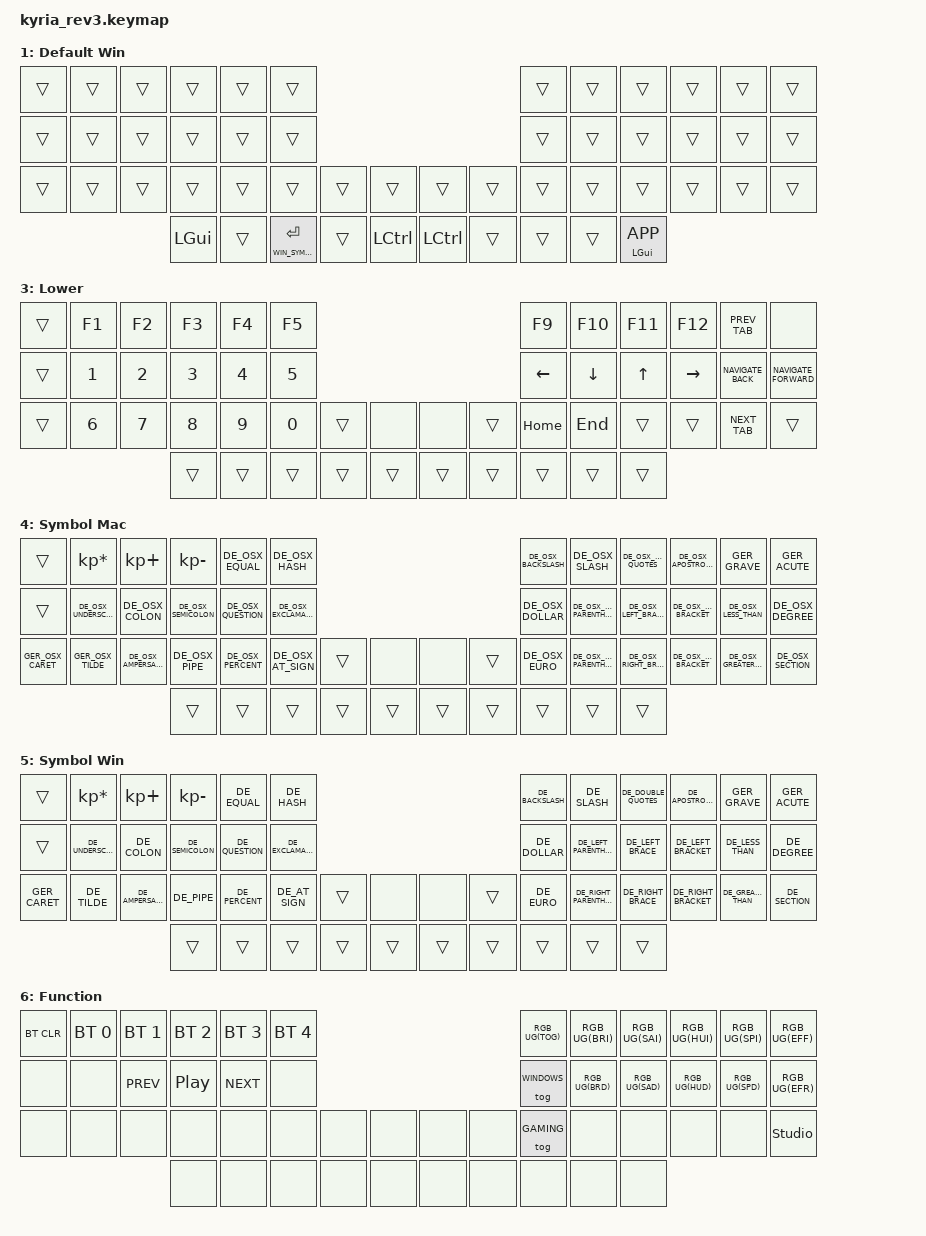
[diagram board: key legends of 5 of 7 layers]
/*
 * Copyright (c) 2023 The ZMK Contributors
 *
 * SPDX-License-Identifier: MIT
 */

#include <behaviors.dtsi>
#include <dt-bindings/zmk/bt.h>
#include <dt-bindings/zmk/keys.h>
#include <dt-bindings/zmk/rgb.h>

// https://github.com/joelspadin/zmk-locale-generator v1.4.0
#include "keys_de.h"
#include "keys_de_osx.h"

// Uncomment this block if using RGB
&led_strip {
    chain-length = <6>;
    // chain-length = <31>; // Uncomment if using both per-key and underglow LEDs
    // chain-length = <25>; // Uncomment if using only per-key LEDs.
};

&sensors {
    triggers-per-rotation = <36>;
};

// DIFFICULTY_THRESHOLD specifies your level of expertise with this keymap.
// It's meant to help newcomers gradually work their way up to mastery.
// You can disable this setting by omitting it or assigning a `0` zero.
#define DIFFICULTY_THRESHOLD 250 // 500ms: easy -> 100ms: hard

#if defined(DIFFICULTY_THRESHOLD) && DIFFICULTY_THRESHOLD > 0

    #define HOLDING_TIME DIFFICULTY_THRESHOLD

    #define PINKEY_DIFFICULTY_OFFSET (DIFFICULTY_THRESHOLD / 8)

    #define TAP_DANCE_TAPPING_TIME (DIFFICULTY_THRESHOLD - 25)

#else

    #define PINKEY_DIFFICULTY_OFFSET 0

    #define TAP_DANCE_TAPPING_TIME 200

#endif

//////////////////////////////////////////////////////////////////////////
//
// Miryoku layers and home row mods (ported from my QMK endgame)
// - https://sunaku.github.io/home-row-mods.html#porting-to-zmk
// - https://github.com/urob/zmk-config#timeless-homerow-mods
//
//////////////////////////////////////////////////////////////////////////

// HOLDING_TYPE defines the flavor of ZMK hold-tap behavior to use
// for the pinky, ring, and middle fingers (which are assigned to Super,
// Alt, and Ctrl respectively in the Miryoku system) on home row keys.
#define HOLDING_TYPE "tap-preferred"

// HOLDING_TIME defines how long you need to hold (milliseconds)
// home row mod keys in order to send their modifiers to the computer
// (i.e. "register" them) for mod-click mouse usage (e.g. Ctrl-Click).
#ifndef HOLDING_TIME
    #define HOLDING_TIME 270 // TAPPING_TERM + ALLOW_CROSSOVER_AFTER
#endif

// STREAK_DECAY defines how long you need to wait (milliseconds)
// after typing before you can use home row mods again. It prevents
// unintended activation of home row mods when you're actively typing.
#define STREAK_DECAY 250

// REPEAT_DECAY defines how much time you have left (milliseconds)
// after tapping a key to hold it again in order to make it auto-repeat.
#define REPEAT_DECAY 150 // "tap then hold" for key auto-repeat

// Home row mods
/ {
    behaviors {
        /*
           key positions index for positional hold-tap

           ┏━━━━━━━━━━━━━━━━━━━━━━━━━━━━━┳━━━━━━━━━━━━━━━━━━━━━━━━━━━━━┓
           ┃ LEFT_HAND_KEYS              ┃             RIGHT_HAND_KEYS ┃
           ┃    0  1  2  3  4  5         ┃         6  7  8  9 10 11    ┃
           ┃    12 13 14 15 16 17        ┃        18 19 20 21 22 23    ┃
           ┃    24 25 26 27 28 29  30 31 ┃ 32 33  34 35 36 37 38 39    ┃
           ┃              40 41 42 43 44 ┃ 45 46 47 48 49              ┃
           ┗━━━━━━━━━━━━━━━━━━━━━━━━━━━━━┻━━━━━━━━━━━━━━━━━━━━━━━━━━━━━┛
        */
        #define LEFT_HAND_KEYS    \
            0  1  2  3  4  5      \
            12 13 14 15 16 17     \
            24 25 26 27 28 29
        #define RIGHT_HAND_KEYS   \
                                         6  7  8  9 10 11 \
                                        18 19 20 21 22 23 \
                                        34 35 36 37 38 39
        #define THUMB_KEYS        \
                            30 31   32 33                 \
                   40 41 42 43 44   45 46 47 48 49

        left_pinky: homey_left_pinky {
            compatible = "zmk,behavior-hold-tap";
            flavor = HOLDING_TYPE;
            hold-trigger-key-positions = <RIGHT_HAND_KEYS THUMB_KEYS>;
            hold-trigger-on-release; // wait for other home row mods
            tapping-term-ms = <(HOLDING_TIME + PINKEY_DIFFICULTY_OFFSET)>;
            quick-tap-ms = <REPEAT_DECAY>;
            require-prior-idle-ms = <STREAK_DECAY>;
            #binding-cells = <2>;
            bindings = <&kp>, <&kp>;
        };

        right_pinky: homey_right_pinky {
            compatible = "zmk,behavior-hold-tap";
            flavor = HOLDING_TYPE;
            hold-trigger-key-positions = <LEFT_HAND_KEYS THUMB_KEYS>;
            hold-trigger-on-release; // wait for other home row mods
            tapping-term-ms = <(HOLDING_TIME + PINKEY_DIFFICULTY_OFFSET)>;
            quick-tap-ms = <REPEAT_DECAY>;
            require-prior-idle-ms = <STREAK_DECAY>;
            #binding-cells = <2>;
            bindings = <&kp>, <&kp>;
        };

        left_ring: homey_left_ring {
            compatible = "zmk,behavior-hold-tap";
            flavor = HOLDING_TYPE;
            hold-trigger-key-positions = <RIGHT_HAND_KEYS THUMB_KEYS>;
            hold-trigger-on-release; // wait for other home row mods
            tapping-term-ms = <HOLDING_TIME>;
            quick-tap-ms = <REPEAT_DECAY>;
            require-prior-idle-ms = <STREAK_DECAY>;
            #binding-cells = <2>;
            bindings = <&kp>, <&kp>;
        };

        right_ring: homey_right_ring {
            compatible = "zmk,behavior-hold-tap";
            flavor = HOLDING_TYPE;
            hold-trigger-key-positions = <LEFT_HAND_KEYS THUMB_KEYS>;
            hold-trigger-on-release; // wait for other home row mods
            tapping-term-ms = <HOLDING_TIME>;
            quick-tap-ms = <REPEAT_DECAY>;
            require-prior-idle-ms = <STREAK_DECAY>;
            #binding-cells = <2>;
            bindings = <&kp>, <&kp>;
        };

        left_middy: homey_left_middy {
            compatible = "zmk,behavior-hold-tap";
            flavor = HOLDING_TYPE;
            hold-trigger-key-positions = <RIGHT_HAND_KEYS THUMB_KEYS>;
            hold-trigger-on-release; // wait for other home row mods
            tapping-term-ms = <HOLDING_TIME>;
            quick-tap-ms = <REPEAT_DECAY>;
            require-prior-idle-ms = <STREAK_DECAY>;
            #binding-cells = <2>;
            bindings = <&kp>, <&kp>;
        };

        right_middy: homey_right_middy {
            compatible = "zmk,behavior-hold-tap";
            flavor = HOLDING_TYPE;
            hold-trigger-key-positions = <LEFT_HAND_KEYS THUMB_KEYS>;
            hold-trigger-on-release; // wait for other home row mods
            tapping-term-ms = <HOLDING_TIME>;
            quick-tap-ms = <REPEAT_DECAY>;
            require-prior-idle-ms = <STREAK_DECAY>;
            #binding-cells = <2>;
            bindings = <&kp>, <&kp>;
        };

        long_press: long_press {
            compatible = "zmk,behavior-hold-tap";
            flavor = "tap-preferred";
            tapping-term-ms = <HOLDING_TIME>;
            quick-tap-ms = <REPEAT_DECAY>;
            // require-prior-idle-ms = <STREAK_DECAY>;
            #binding-cells = <2>;
            bindings = <&kp>, <&kp>;
        };

        sk_shft: sticky_key_shift {
            compatible = "zmk,behavior-sticky-key";
            #binding-cells = <1>;
            bindings = <&kp>;
            release-after-ms = <TAP_DANCE_TAPPING_TIME>;
        };
    };
};

#define HRM_L(mod_key1, mod_key2, mod_key3) &left_pinky mod_key1 &left_ring mod_key2 &left_middy mod_key3
#define HRM_R(mod_key1, mod_key2, mod_key3) &right_pinky mod_key1 &right_ring mod_key2 &right_middy mod_key3

#define RGB_UG(action) &rgb_ug RGB_##action

#define DE_AE DE_A_UMLAUT
#define DE_OE DE_O_UMLAUT
#define DE_UE DE_U_UMLAUT

/ {
    macros {
        // ^
        ZMK_MACRO(GER_CARET,
            bindings
                = <&kp DE_CARET>
                , <&kp SPACE>;
        )

        ZMK_MACRO(GER_OSX_CARET,
            bindings
                = <&kp DE_OSX_CARET>
                , <&kp SPACE>;
        )

        // ~
        ZMK_MACRO(GER_OSX_TILDE,
            bindings
                = <&kp DE_OSX_TILDE>
                , <&kp SPACE>;
        )

        // `
        ZMK_MACRO(GER_GRAVE,
            bindings
                = <&kp DE_GRAVE>
                , <&kp SPACE>;
        )

        // ´
        ZMK_MACRO(GER_ACUTE,
            bindings
                = <&kp DE_ACUTE>
                , <&kp SPACE>;
        )

        ZMK_MACRO(PREV_TAB,
            bindings = <&kp LC(LS(TAB))>;
        )

        ZMK_MACRO(NEXT_TAB,
            bindings = <&kp LC(TAB)>;
        )

        ZMK_MACRO(NAVIGATE_BACK,
            bindings = <&kp LC(LEFT)>;
        )

        ZMK_MACRO(NAVIGATE_FORWARD,
            bindings = <&kp LC(RIGHT)>;
        )

        TD_PLAY_SKIP: TD_PLAY_SKIP {
            compatible = "zmk,behavior-tap-dance";
            #binding-cells = <0>;
            tapping-term-ms = <250>;
            bindings = <&kp C_PLAY_PAUSE>, <&kp C_NEXT>;
        };
    };
};

// Layers
#define MAC 0
#define WINDOWS 1
#define GAMING 2
#define LOWER 3
#define MAC_SYMBOL 4
#define WIN_SYMBOL 5
#define FUNCTION 6

/ {
    conditional_layers {
        compatible = "zmk,conditional-layers";
        tri_layer {
            if-layers = <LOWER WIN_SYMBOL>;
            then-layer = <FUNCTION>;
        };
        tri_layer_mac {
            if-layers = <LOWER MAC_SYMBOL>;
            then-layer = <FUNCTION>;
        };
    };
};

/ {
    keymap {
        compatible = "zmk,keymap";

        default_mac_layer {
            display-name = "Default Mac";
            bindings = <
//┏━━━━━━━━━━━━━━┳━━━━━━━━━━━━━━━━┳━━━━━━━━━━┳━━━━━━━━━━━━━┳━━━━━━━━━━━━━━━┳━━━━━━━━━━━━━━━━━━━━┓                                                                     ┏━━━━━━━━━━━━┳━━━━━━━━━━━━━━━┳━━━━━━━━━━━━━━━━━┳━━━━━━━━━━┳━━━━━━━━━━━┳━━━━━━━━━━━━━━━━━━━━┓
     &kp TAB            &kp Q        &kp W       &kp F        &kp P            &kp B                                                                                     &kp K           &kp L           &kp U         &kp DE_Z   &kp DE_OE       &kp DE_UE
//┣━━━━━━━━━━━━━━╋━━━━━━━━━━━━━━━━╋━━━━━━━━━━╋━━━━━━━━━━━━━╋━━━━━━━━━━━━━━━╋━━━━━━━━━━━━━━━━━━━━┫                                                                     ┣━━━━━━━━━━━━╋━━━━━━━━━━━━━━━╋━━━━━━━━━━━━━━━━━╋━━━━━━━━━━╋━━━━━━━━━━━╋━━━━━━━━━━━━━━━━━━━━┫
     &kp ESC        HRM_L(LGUI A  ,  LALT R  ,  LCTRL S    )  &lt LOWER T      &kp G                                                                                     &kp M        &lt LOWER N     HRM_R(RCTRL E  ,  LALT I  ,   LGUI O  )     &kp DE_AE
//┣━━━━━━━━━━━━━━╋━━━━━━━━━━━━━━━━╋━━━━━━━━━━╋━━━━━━━━━━━━━╋━━━━━━━━━━━━━━━╋━━━━━━━━━━━━━━━━━━━━╋━━━━━━━━━━━━━━┳━━━━━━━━━━━━━━━━━┓ ┏━━━━━━━━━━━━━━┳━━━━━━━━━━━━━━━━━━━╋━━━━━━━━━━━━╋━━━━━━━━━━━━━━━╋━━━━━━━━━━━━━━━━━╋━━━━━━━━━━╋━━━━━━━━━━━╋━━━━━━━━━━━━━━━━━━━━┫
     &tog LOWER       &kp DE_Y       &kp X       &kp C        &kp D            &kp V                 &kp DEL      &TD_PLAY_SKIP       &kp C_MUTE         &kp DEL         &kp J           &kp H          &kp COMMA      &kp DOT    &kp DE_SZ   &kp K_CONTEXT_MENU
//┗━━━━━━━━━━━━━━┻━━━━━━━━━━━━━━━━┻━━━━━━━━━━╋━━━━━━━━━━━━━╋━━━━━━━━━━━━━━━╋━━━━━━━━━━━━━━━━━━━━╋━━━━━━━━━━━━━━╋━━━━━━━━━━━━━━━━━┫ ┣━━━━━━━━━━━━━━╋━━━━━━━━━━━━━━━━━━━╋━━━━━━━━━━━━╋━━━━━━━━━━━━━━━╋━━━━━━━━━━━━━━━━━╋━━━━━━━━━━┻━━━━━━━━━━━┻━━━━━━━━━━━━━━━━━━━━┛
                                                &kp LCTRL     &kp LALT       &lt MAC_SYMBOL RET    &kp LSHIFT       &kp LGUI            &kp LGUI     &lt LOWER SPACE     &kp BSPC      &kp LALT      &mt RCTRL K_APP  
//                                           ┗━━━━━━━━━━━━━┻━━━━━━━━━━━━━━━┻━━━━━━━━━━━━━━━━━━━━┻━━━━━━━━━━━━━━┻━━━━━━━━━━━━━━━━━┛ ┗━━━━━━━━━━━━━━┻━━━━━━━━━━━━━━━━━━━┻━━━━━━━━━━━━┻━━━━━━━━━━━━━━━┻━━━━━━━━━━━━━━━━━┛
            >;

            sensor-bindings =
                <&inc_dec_kp 0 0>,
                <&inc_dec_kp C_VOLUME_UP C_VOLUME_DOWN>;
        };

        default_windows_layer {
            display-name = "Default Win";
            bindings = <
//┏━━━━━━━━━━┳━━━━━━━━━━┳━━━━━━━━━━┳━━━━━━━━━━┳━━━━━━━━━━┳━━━━━━━━━━━━━━━━━━━┓                                             ┏━━━━━━━━━━┳━━━━━━━━━━┳━━━━━━━━━━━━━━━━┳━━━━━━━━━━┳━━━━━━━━━━┳━━━━━━━━━━┓
     &trans     &trans     &trans     &trans     &trans      &trans                                                           &trans     &trans        &trans        &trans     &trans     &trans
//┣━━━━━━━━━━┳━━━━━━━━━━┳━━━━━━━━━━┳━━━━━━━━━━┳━━━━━━━━━━┳━━━━━━━━━━━━━━━━━━━┫                                             ┣━━━━━━━━━━┳━━━━━━━━━━┳━━━━━━━━━━━━━━━━┳━━━━━━━━━━┳━━━━━━━━━━┳━━━━━━━━━━┫
     &trans     &trans     &trans     &trans     &trans      &trans                                                           &trans     &trans        &trans        &trans     &trans     &trans
//┣━━━━━━━━━━╋━━━━━━━━━━╋━━━━━━━━━━╋━━━━━━━━━━╋━━━━━━━━━━╋━━━━━━━━━━━━━━━━━━━╋━━━━━━━━━━┳━━━━━━━━━━┓ ┏━━━━━━━━━━┳━━━━━━━━━━╋━━━━━━━━━━╋━━━━━━━━━━╋━━━━━━━━━━━━━━━━╋━━━━━━━━━━╋━━━━━━━━━━╋━━━━━━━━━━┫
     &trans     &trans     &trans     &trans     &trans      &trans             &trans     &trans      &trans      &trans     &trans     &trans        &trans        &trans     &trans     &trans
//┗━━━━━━━━━━┻━━━━━━━━━━┻━━━━━━━━━━╋━━━━━━━━━━╋━━━━━━━━━━╋━━━━━━━━━━━━━━━━━━━╋━━━━━━━━━━╋━━━━━━━━━━┫ ┣━━━━━━━━━━╋━━━━━━━━━━╋━━━━━━━━━━╋━━━━━━━━━━╋━━━━━━━━━━━━━━━━╋━━━━━━━━━━┻━━━━━━━━━━┻━━━━━━━━━━┛
                                     &kp LGUI    &trans   &lt WIN_SYMBOL RET    &trans   &kp LCTRL    &kp LCTRL    &trans     &trans     &trans    &mt LGUI K_APP
//                                 ┗━━━━━━━━━━┻━━━━━━━━━━┻━━━━━━━━━━━━━━━━━━━┻━━━━━━━━━━┻━━━━━━━━━━┛ ┗━━━━━━━━━━┻━━━━━━━━━━┻━━━━━━━━━━┻━━━━━━━━━━┻━━━━━━━━━━━━━━━━┛
            >;

            sensor-bindings =
                <&inc_dec_kp 0 0>,
                <&inc_dec_kp C_VOLUME_UP C_VOLUME_DOWN>;
        };

        /*
        ┏━━━━━━━┳━━━━━┳━━━━━┳━━━━━┳━━━━━┳━━━━━┓                   ┏━━━━━┳━━━━━┳━━━━━┳━━━━━┳━━━━━┳━━━━━━┓
        ┃  Tab  ┃  T  ┃  Q  ┃  X  ┃  E  ┃  R  ┃                   ┃  Z  ┃  U  ┃  I  ┃  O  ┃  Ö  ┃  Ü   ┃
        ┃  Esc  ┃Shift┃  A  ┃  W  ┃  D  ┃  F  ┣━━━━━┳━━━━━┓       ┃  H  ┃  J  ┃  K  ┃  L  ┃  P  ┃  Ä   ┃
        ┃ Lower ┃  B  ┃  Y  ┃  S  ┃  C  ┃  V  ┃  G  ┃ ⏯/⏭ ┃       ┃  N  ┃  M  ┃  ,  ┃  .  ┃  ß  ┃Tog Gm┃
        ┗━━━━━━━┻━━━━━┻━━━━━╋━━━━━╋━━━━━╋━━━━━╋━━━━━╋━━━━━┫       ┗━━━━━┻━━━━━┻━━━━━┻━━━━━┻━━━━━┻━━━━━━┛
                            ┃ GUI ┃ ALT ┃ RET ┃SPACE┃CTRL ┃
                            ┗━━━━━┻━━━━━┻━━━━━┻━━━━━┻━━━━━┛
        */
        gaming_layer {
            display-name = "Gaming";
            bindings = <
    &trans &kp T      &kp Q     &kp X    &kp E    &kp R                                          &kp DE_Z   &kp U   &kp I          &kp O   &trans  &trans
    &trans &kp LSHIFT &kp A     &kp W    &kp D    &kp F                                          &kp H      &kp J   HRM_R(RCTRL K, LALT L, LGUI P) &trans
    &trans &kp B      &kp DE_Y  &kp S    &kp C    &kp V   &kp G     &trans       &trans &trans   &kp N      &kp M   &kp COMMA      &kp DOT &trans  &tog GAMING
                                &trans   &kp LALT &kp RET &kp SPACE &trans       &trans &trans   &trans     &trans          &trans
            >;
        };

        /*
        ┏━━━━┳━━━━┳━━━━┳━━━━┳━━━━┳━━━━┓ ┏━━━━━━┳━━━━━┳━━━━━┳━━━━━┳━━━━━━┳━━━━━━━━━┓
        ┃    ┃ F1 ┃ F2 ┃ F3 ┃ F4 ┃ F5 ┃ ┃ F9   ┃ F10 ┃ F11 ┃ F12 ┃ Prev ┃         ┃
        ┃    ┃ 1  ┃ 2  ┃ 3  ┃ 4  ┃ 5  ┃ ┃  ←   ┃  ↓  ┃  ↑  ┃  →  ┃ Back ┃ Forward ┃
        ┃    ┃ 6  ┃ 7  ┃ 8  ┃ 9  ┃ 0  ┃ ┃ Home ┃ End ┃     ┃     ┃ Next ┃         ┃
        ┗━━━━┻━━━━┻━━━━┻━━━━┻━━━━┻━━━━┛ ┗━━━━━━┻━━━━━┻━━━━━┻━━━━━┻━━━━━━┻━━━━━━━━━┛
        */
        lower_layer {
            display-name = "Lower";
            bindings = <
//┏━━━━━━━━━┳━━━━━━━━━━┳━━━━━━━━━━┳━━━━━━━━━━┳━━━━━━━━━━┳━━━━━━━━━━┓                                      ┏━━━━━━━━━━┳━━━━━━━━━━┳━━━━━━━━━━┳━━━━━━━━━━┳━━━━━━━━━━━━━━━┳━━━━━━━━━━━━━━━━━━━━┓
    &trans     &kp F1     &kp F2     &kp F3     &kp F4     &kp F5                                            &kp F9    &kp F10    &kp F11    &kp F12      &PREV_TAB     &none
//┣━━━━━━━━━╋━━━━━━━━━━╋━━━━━━━━━━╋━━━━━━━━━━╋━━━━━━━━━━╋━━━━━━━━━━┫                                      ┣━━━━━━━━━━╋━━━━━━━━━━╋━━━━━━━━━━╋━━━━━━━━━━╋━━━━━━━━━━━━━━━╋━━━━━━━━━━━━━━━━━━━━┫
    &trans     &kp N1     &kp N2     &kp N3     &kp N4     &kp N5                                           &kp LEFT   &kp DOWN   &kp UP    &kp RIGHT  &NAVIGATE_BACK   &NAVIGATE_FORWARD
//┣━━━━━━━━━╋━━━━━━━━━━╋━━━━━━━━━━╋━━━━━━━━━━╋━━━━━━━━━━╋━━━━━━━━━━╋━━━━━━━━┳━━━━━━━━┓ ┏━━━━━━━━┳━━━━━━━━━╋━━━━━━━━━━╋━━━━━━━━━━╋━━━━━━━━━━╋━━━━━━━━━━╋━━━━━━━━━━━━━━━╋━━━━━━━━━━━━━━━━━━━━┫
    &trans     &kp N6     &kp N7     &kp N8     &kp N9     &kp N0    &trans   &none      &none    &trans    &kp HOME   &kp END    &trans     &trans       &NEXT_TAB     &trans
//┗━━━━━━━━━┻━━━━━━━━━━┻━━━━━━━━━━╋━━━━━━━━━━╋━━━━━━━━━━╋━━━━━━━━━━╋━━━━━━━━╋━━━━━━━━┫ ┣━━━━━━━━╋━━━━━━━━━╋━━━━━━━━━━╋━━━━━━━━━━╋━━━━━━━━━━╋━━━━━━━━━━┻━━━━━━━━━━━━━━━┻━━━━━━━━━━━━━━━━━━━━┛
                                     &trans     &trans     &trans    &trans   &trans     &trans   &trans    &trans     &trans     &trans
//                                ┗━━━━━━━━━━┻━━━━━━━━━━┻━━━━━━━━━━┻━━━━━━━━┻━━━━━━━━┛ ┗━━━━━━━━┻━━━━━━━━━┻━━━━━━━━━━┻━━━━━━━━━━┻━━━━━━━━━━┛
            >;

            sensor-bindings =
                <&inc_dec_kp 0 0>,
                <&inc_dec_kp UP DOWN>;
        };

        /*
        ┏━━━┳━━━┳━━━┳━━━┳━━━┳━━━┓    ┏━━━┳━━━┳━━━┳━━━┳━━━┳━━━┓
        ┃ □ ┃ * ┃ + ┃ - ┃ = ┃ # ┃    ┃ \ ┃ / ┃ " ┃ ' ┃ ` ┃ ´ ┃
        ┃ □ ┃ _ ┃ : ┃ ; ┃ ? ┃ ! ┃    ┃ $ ┃ ( ┃ { ┃ [ ┃ < ┃ ° ┃
        ┃ ^ ┃ ~ ┃ & ┃ | ┃ % ┃ @ ┃    ┃ € ┃ ) ┃ } ┃ ] ┃ > ┃ § ┃
        ┗━━━┻━━━┻━━━┻━━━┻━━━┻━━━┛    ┗━━━┻━━━┻━━━┻━━━┻━━━┻━━━┛
        */
        mac_symbol_layer {
            display-name = "Symbol Mac";
            bindings = <
//┏━━━━━━━━━━━━━━━━┳━━━━━━━━━━━━━━━━━━━━┳━━━━━━━━━━━━━━━━━━━━┳━━━━━━━━━━━━━━━━━━━━┳━━━━━━━━━━━━━━━━━━━━┳━━━━━━━━━━━━━━━━━━━━┓                                     ┏━━━━━━━━━━━━━━━━━━━━┳━━━━━━━━━━━━━━━━━━━━━━━━━━━━━━┳━━━━━━━━━━━━━━━━━━━━━━━━━┳━━━━━━━━━━━━━━━━━━━━━━━━━┳━━━━━━━━━━━━━━━━━━━━━━━┳━━━━━━━━━━━━━━━━━━━━┓
       &trans         &kp KP_MULTIPLY      &kp KP_PLUS          &kp KP_MINUS         &kp DE_OSX_EQUAL    &kp DE_OSX_HASH                                           &kp DE_OSX_BACKSLASH    &kp DE_OSX_SLASH            &kp DE_OSX_DOUBLE_QUOTES   &kp DE_OSX_APOSTROPHE    &GER_GRAVE               &GER_ACUTE
//┣━━━━━━━━━━━━━━━━╋━━━━━━━━━━━━━━━━━━━━╋━━━━━━━━━━━━━━━━━━━━╋━━━━━━━━━━━━━━━━━━━━╋━━━━━━━━━━━━━━━━━━━━╋━━━━━━━━━━━━━━━━━━━━┫                                     ┣━━━━━━━━━━━━━━━━━━━━╋━━━━━━━━━━━━━━━━━━━━━━━━━━━━━━╋━━━━━━━━━━━━━━━━━━━━━━━━━╋━━━━━━━━━━━━━━━━━━━━━━━━━╋━━━━━━━━━━━━━━━━━━━━━━━╋━━━━━━━━━━━━━━━━━━━━┫
       &trans       &kp DE_OSX_UNDERSCORE  &kp DE_OSX_COLON   &kp DE_OSX_SEMICOLON &kp DE_OSX_QUESTION  &kp DE_OSX_EXCLAMATION                                      &kp DE_OSX_DOLLAR    &kp DE_OSX_LEFT_PARENTHESIS    &kp DE_OSX_LEFT_BRACE     &kp DE_OSX_LEFT_BRACKET  &kp DE_OSX_LESS_THAN     &kp DE_OSX_DEGREE
//┣━━━━━━━━━━━━━━━━╋━━━━━━━━━━━━━━━━━━━━╋━━━━━━━━━━━━━━━━━━━━╋━━━━━━━━━━━━━━━━━━━━╋━━━━━━━━━━━━━━━━━━━━╋━━━━━━━━━━━━━━━━━━━━╋━━━━━━━━┳━━━━━━━━┓ ┏━━━━━━━━┳━━━━━━━━╋━━━━━━━━━━━━━━━━━━━━╋━━━━━━━━━━━━━━━━━━━━━━━━━━━━━━╋━━━━━━━━━━━━━━━━━━━━━━━━━╋━━━━━━━━━━━━━━━━━━━━━━━━━╋━━━━━━━━━━━━━━━━━━━━━━━╋━━━━━━━━━━━━━━━━━━━━┫
    &GER_OSX_CARET     &GER_OSX_TILDE    &kp DE_OSX_AMPERSAND   &kp DE_OSX_PIPE     &kp DE_OSX_PERCENT   &kp DE_OSX_AT_SIGN   &trans   &none      &none    &trans    &kp DE_OSX_EURO     &kp DE_OSX_RIGHT_PARENTHESIS   &kp DE_OSX_RIGHT_BRACE    &kp DE_OSX_RIGHT_BRACKET &kp DE_OSX_GREATER_THAN  &kp DE_OSX_SECTION
//┗━━━━━━━━━━━━━━━━┻━━━━━━━━━━━━━━━━━━━━┻━━━━━━━━━━━━━━━━━━━━╋━━━━━━━━━━━━━━━━━━━━╋━━━━━━━━━━━━━━━━━━━━╋━━━━━━━━━━━━━━━━━━━━╋━━━━━━━━╋━━━━━━━━┫ ┣━━━━━━━━╋━━━━━━━━╋━━━━━━━━━━━━━━━━━━━━╋━━━━━━━━━━━━━━━━━━━━━━━━━━━━━━╋━━━━━━━━━━━━━━━━━━━━━━━━━╋━━━━━━━━━━━━━━━━━━━━━━━━━┻━━━━━━━━━━━━━━━━━━━━━━━┻━━━━━━━━━━━━━━━━━━━━┛
                                                                &trans               &trans              &trans               &trans   &trans     &trans   &trans    &trans              &trans                         &trans
//                                                           ┗━━━━━━━━━━━━━━━━━━━━┻━━━━━━━━━━━━━━━━━━━━┻━━━━━━━━━━━━━━━━━━━━┻━━━━━━━━┻━━━━━━━━┛ ┗━━━━━━━━┻━━━━━━━━┻━━━━━━━━━━━━━━━━━━━━┻━━━━━━━━━━━━━━━━━━━━━━━━━━━━━━┻━━━━━━━━━━━━━━━━━━━━━━━━━┛
            >;
        };

        windows_symbol_layer {
            display-name = "Symbol Win";
            bindings = <
//┏━━━━━━━━━━━━┳━━━━━━━━━━━━━━━━━━━━┳━━━━━━━━━━━━━━━━━━━━┳━━━━━━━━━━━━━━━━━━━━┳━━━━━━━━━━━━━━━━━━━━┳━━━━━━━━━━━━━━━━━━━━┓                                     ┏━━━━━━━━━━━━━━━━━━━━┳━━━━━━━━━━━━━━━━━━━━━━━━━┳━━━━━━━━━━━━━━━━━━━━┳━━━━━━━━━━━━━━━━━━━━┳━━━━━━━━━━━━━━━━━━━━┳━━━━━━━━━━━━━━━━━━━━┓
    &trans       &kp KP_MULTIPLY       &kp KP_PLUS          &kp KP_MINUS         &kp DE_EQUAL        &kp DE_HASH                                                 &kp DE_BACKSLASH    &kp DE_SLASH             &kp DE_DOUBLE_QUOTES &kp DE_APOSTROPHE    &GER_GRAVE             &GER_ACUTE
//┣━━━━━━━━━━━━╋━━━━━━━━━━━━━━━━━━━━╋━━━━━━━━━━━━━━━━━━━━╋━━━━━━━━━━━━━━━━━━━━╋━━━━━━━━━━━━━━━━━━━━╋━━━━━━━━━━━━━━━━━━━━┫                                     ┣━━━━━━━━━━━━━━━━━━━━╋━━━━━━━━━━━━━━━━━━━━━━━━━╋━━━━━━━━━━━━━━━━━━━━╋━━━━━━━━━━━━━━━━━━━━╋━━━━━━━━━━━━━━━━━━━━╋━━━━━━━━━━━━━━━━━━━━┫
    &trans       &kp DE_UNDERSCORE     &kp DE_COLON         &kp DE_SEMICOLON     &kp DE_QUESTION     &kp DE_EXCLAMATION                                          &kp DE_DOLLAR       &kp DE_LEFT_PARENTHESIS  &kp DE_LEFT_BRACE    &kp DE_LEFT_BRACKET  &kp DE_LESS_THAN       &kp DE_DEGREE
//┣━━━━━━━━━━━━╋━━━━━━━━━━━━━━━━━━━━╋━━━━━━━━━━━━━━━━━━━━╋━━━━━━━━━━━━━━━━━━━━╋━━━━━━━━━━━━━━━━━━━━╋━━━━━━━━━━━━━━━━━━━━╋━━━━━━━━┳━━━━━━━━┓ ┏━━━━━━━━┳━━━━━━━━╋━━━━━━━━━━━━━━━━━━━━╋━━━━━━━━━━━━━━━━━━━━━━━━━╋━━━━━━━━━━━━━━━━━━━━╋━━━━━━━━━━━━━━━━━━━━╋━━━━━━━━━━━━━━━━━━━━╋━━━━━━━━━━━━━━━━━━━━┫
    &GER_CARET   &kp DE_TILDE          &kp DE_AMPERSAND     &kp DE_PIPE          &kp DE_PERCENT      &kp DE_AT_SIGN       &trans   &none      &none    &trans    &kp DE_EURO         &kp DE_RIGHT_PARENTHESIS &kp DE_RIGHT_BRACE   &kp DE_RIGHT_BRACKET &kp DE_GREATER_THAN    &kp DE_SECTION
//┗━━━━━━━━━━━━┻━━━━━━━━━━━━━━━━━━━━┻━━━━━━━━━━━━━━━━━━━━╋━━━━━━━━━━━━━━━━━━━━╋━━━━━━━━━━━━━━━━━━━━╋━━━━━━━━━━━━━━━━━━━━╋━━━━━━━━╋━━━━━━━━┫ ┣━━━━━━━━╋━━━━━━━━╋━━━━━━━━━━━━━━━━━━━━╋━━━━━━━━━━━━━━━━━━━━━━━━━╋━━━━━━━━━━━━━━━━━━━━╋━━━━━━━━━━━━━━━━━━━━┻━━━━━━━━━━━━━━━━━━━━┻━━━━━━━━━━━━━━━━━━━━┛
                                                            &trans               &trans              &trans               &trans   &trans     &trans   &trans    &trans              &trans                   &trans
//                                                       ┗━━━━━━━━━━━━━━━━━━━━┻━━━━━━━━━━━━━━━━━━━━┻━━━━━━━━━━━━━━━━━━━━┻━━━━━━━━┻━━━━━━━━┛ ┗━━━━━━━━┻━━━━━━━━┻━━━━━━━━━━━━━━━━━━━━┻━━━━━━━━━━━━━━━━━━━━━━━━━┻━━━━━━━━━━━━━━━━━━━━┛
            >;
        };

        /*
        ┏━━━━━━┳━━━━━━┳━━━━━━┳━━━━━━┳━━━━━━┳━━━━━━┓       ┏━━━━━━━━━━━┳━━━━━━━━━━━━━━━━┳━━━━━━━━━━━━━┳━━━━━━━━━━━━━┳━━━━━━━━━━━━━━━┳━━━━━━━━━━━━━━━┓
        ┃BT_CLR┃ BT 0 ┃ BT 1 ┃ BT 2 ┃ BT 3 ┃ BT 4 ┃       ┃RGB Toggle ┃Bright increase ┃Sat increase ┃Hue increase ┃Speed increase ┃Effect forward ┃
        ┃      ┃      ┃  ⏮   ┃  ⏯   ┃  ⏭   ┃      ┃       ┃Toggle Win ┃Bright decrease ┃Sat decrease ┃Hue decrease ┃Speed increase ┃Effect reverse ┃
        ┃      ┃      ┃      ┃      ┃      ┃      ┃       ┃Toggle Game┃                ┃             ┃             ┃               ┃               ┃
        ┃      ┃      ┃      ┃      ┃      ┃      ┃       ┃           ┃                ┃             ┃             ┃               ┃ studio_unlock ┃
        ┗━━━━━━┻━━━━━━┻━━━━━━┻━━━━━━┻━━━━━━┻━━━━━━┛       ┗━━━━━━━━━━━┻━━━━━━━━━━━━━━━━┻━━━━━━━━━━━━━┻━━━━━━━━━━━━━┻━━━━━━━━━━━━━━━┻━━━━━━━━━━━━━━━┛
        */ 
        function_layer {
            display-name = "Function";
            bindings = <
//┏━━━━━━━━━━┳━━━━━━━━━━━━━━━┳━━━━━━━━━━━━━━━┳━━━━━━━━━━━━━━━━━━━━┳━━━━━━━━━━━━━━━┳━━━━━━━━━━━━━━━┓                                     ┏━━━━━━━━━━━━━━━┳━━━━━━━━━━━━━━━┳━━━━━━━━━━━━━━━┳━━━━━━━━━━━━━━━┳━━━━━━━━━━━━━━━┳━━━━━━━━━━━━━━━┓
   &bt BT_CLR  &bt BT_SEL 0    &bt BT_SEL 1    &bt BT_SEL 2         &bt BT_SEL 3    &bt BT_SEL 4                                           RGB_UG(TOG)     RGB_UG(BRI)     RGB_UG(SAI)     RGB_UG(HUI)     RGB_UG(SPI)     RGB_UG(EFF)
//┣━━━━━━━━━━╋━━━━━━━━━━━━━━━╋━━━━━━━━━━━━━━━╋━━━━━━━━━━━━━━━━━━━━╋━━━━━━━━━━━━━━━╋━━━━━━━━━━━━━━━┫                                     ┣━━━━━━━━━━━━━━━╋━━━━━━━━━━━━━━━╋━━━━━━━━━━━━━━━╋━━━━━━━━━━━━━━━╋━━━━━━━━━━━━━━━╋━━━━━━━━━━━━━━━┫
   &none       &none           &kp C_PREV      &kp C_PLAY_PAUSE     &kp C_NEXT      &none                                                  &tog WINDOWS    RGB_UG(BRD)     RGB_UG(SAD)     RGB_UG(HUD)     RGB_UG(SPD)     RGB_UG(EFR)
//┣━━━━━━━━━━╋━━━━━━━━━━━━━━━╋━━━━━━━━━━━━━━━╋━━━━━━━━━━━━━━━━━━━━╋━━━━━━━━━━━━━━━╋━━━━━━━━━━━━━━━╋━━━━━━━━┳━━━━━━━━┓ ┏━━━━━━━━┳━━━━━━━━╋━━━━━━━━━━━━━━━╋━━━━━━━━━━━━━━━╋━━━━━━━━━━━━━━━╋━━━━━━━━━━━━━━━╋━━━━━━━━━━━━━━━╋━━━━━━━━━━━━━━━┫
   &none       &none           &none           &none                &none           &none           &none    &none      &none    &none     &tog GAMING     &none           &none           &none           &none         &studio_unlock
//┗━━━━━━━━━━┻━━━━━━━━━━━━━━━┻━━━━━━━━━━━━━━━╋━━━━━━━━━━━━━━━━━━━━╋━━━━━━━━━━━━━━━╋━━━━━━━━━━━━━━━╋━━━━━━━━╋━━━━━━━━┫ ┣━━━━━━━━╋━━━━━━━━╋━━━━━━━━━━━━━━━╋━━━━━━━━━━━━━━━╋━━━━━━━━━━━━━━━╋━━━━━━━━━━━━━━━┻━━━━━━━━━━━━━━━┻━━━━━━━━━━━━━━━┛
                                               &none                &none           &none           &none    &none      &none    &none     &none           &none           &none
//                                           ┗━━━━━━━━━━━━━━━━━━━━┻━━━━━━━━━━━━━━━┻━━━━━━━━━━━━━━━┻━━━━━━━━┻━━━━━━━━┛ ┗━━━━━━━━┻━━━━━━━━┻━━━━━━━━━━━━━━━┻━━━━━━━━━━━━━━━┻━━━━━━━━━━━━━━━┛
            >;

            sensor-bindings =
                <&inc_dec_kp 0 0>,
                <&inc_dec_kp C_BRIGHTNESS_INC C_BRIGHTNESS_DEC>;
        };
    };
};

